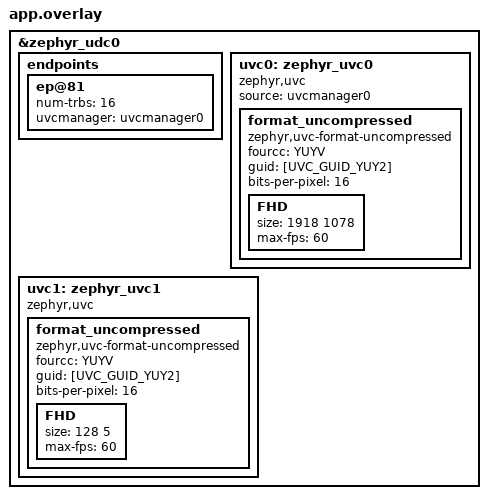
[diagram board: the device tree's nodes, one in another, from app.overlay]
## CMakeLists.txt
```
cmake_minimum_required(VERSION 3.20.0)
find_package(Zephyr REQUIRED HINTS $ENV{ZEPHYR_BASE})
project(app)
target_sources(app PRIVATE src/main.c src/imx219.c src/csrtst.c)

# Run some code from RAM for performance during enumeration
zephyr_code_relocate(LIBRARY drivers__usb__udc LOCATION RAM)
```

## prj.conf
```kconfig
CONFIG_ASSERT=y

# Shell
CONFIG_SHELL=y
CONFIG_I2C_SHELL=y
CONFIG_KERNEL_SHELL=y
CONFIG_SHELL_BACKEND_SERIAL_CHECK_DTR=y

# Logging
CONFIG_LOG=y
CONFIG_LOG_MODE_MINIMAL=y
CONFIG_UDC_DRIVER_LOG_LEVEL_INF=y
CONFIG_USBD_LOG_LEVEL_INF=y
CONFIG_USBD_UVC_LOG_LEVEL_INF=y
CONFIG_VIDEO_LOG_LEVEL_INF=y

# USB
CONFIG_USBD_VIDEO_CLASS=y
CONFIG_USBD_VIDEO_HEADER_SIZE=8

# Video
CONFIG_VIDEO=y
CONFIG_VIDEO_IMX219=y
# CONFIG_VIDEO_IMX219_DUMMY=y
CONFIG_VIDEO_UVCMANAGER=y

# I2C
CONFIG_I2C_PCA9542A_ROOT_INIT_PRIO=1
CONFIG_I2C_PCA9542A_CHANNEL_INIT_PRIO=2
CONFIG_I2C_PCA9542A_IGNORE_FAILURE=y
```

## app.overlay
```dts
#include <zephyr/dt-bindings/usb/video.h>

/*
 * This builds a complete configuration chain through "source = <&...>;":
 * - USB Video Class (UVC), exposing the controls to the host and communicating with it.
 * - UVC Manager, controlled by the UVC class protocol, doing I/O between the sensor and USB.
 * - IMX219 sensor, with configuration coming from the UVC Manager and the host before it.
 */

&zephyr_udc0 {
	endpoints {
		ep@81 {
			num-trbs = <16>;
			uvcmanager = <&uvcmanager0>;
		};
	};

	uvc0: zephyr_uvc0 {
		compatible = "zephyr,uvc";
		source = <&uvcmanager0>;
		status = "okay";

		format_uncompressed {
			compatible = "zephyr,uvc-format-uncompressed", "zephyr,uvc-format";
			fourcc = "YUYV";
			guid = [UVC_GUID_YUY2];
			bits-per-pixel = <16>;

			FHD {
				/* There are 2 rows and columns less as required to do debayer. */
				size = <1918 1078>;
				max-fps = <60>;
			};
		};
	};

	uvc1: zephyr_uvc1 {
		compatible = "zephyr,uvc";
		status = "okay";

		format_uncompressed {
			compatible = "zephyr,uvc-format-uncompressed", "zephyr,uvc-format";
			fourcc = "YUYV";
			guid = [UVC_GUID_YUY2];
			bits-per-pixel = <16>;

			FHD {
				/* There are 2 rows and columns less as required to do debayer. */
				size = <128 5>;
				max-fps = <60>;
			};
		};
	};

};
```

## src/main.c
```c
#include <zephyr/kernel.h>
#include <zephyr/devicetree.h>
#include <zephyr/drivers/video.h>
#include <zephyr/logging/log.h>

LOG_MODULE_REGISTER(app, LOG_LEVEL_DBG);

static const struct device *uvc0_dev = DEVICE_DT_GET(DT_NODELABEL(uvc0));
static const struct device *uvc1_dev = DEVICE_DT_GET(DT_NODELABEL(uvc1));

int main(void)
{
    printf("hello\n");
    k_sleep(K_SECONDS(5));
    printf("test1......\n");

    const struct device *video_dev = DEVICE_DT_GET(DT_NODELABEL(imx219));
    if (video_dev == NULL || !device_is_ready(video_dev))
    {
        printf("Could not get I2C cam device\n");
        return;
    }
	printk("Video device: %s\n", video_dev->name);

}
```

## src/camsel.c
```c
#include <stdio.h>
#include <zephyr/drivers/i2c.h>
#include <zephyr/shell/shell.h>
#define MUX_ADDR 0x71

static void sel_cam() {

    const struct device *mux_dev = DEVICE_DT_GET(DT_NODELABEL(i2c0));
    if (mux_dev == NULL || !device_is_ready(mux_dev))
    {
        printf("Could not get I2C mux device\n");
        return;
    }

	printf("Selecting camera \n\r");
	uint8_t val = 0x4;
	int ret = i2c_reg_write_byte(mux_dev, MUX_ADDR,
                             0, val);
    if (ret)
    {
        printf("Unable write to Cam. (err %i)\n", ret);
        return;
    }
    printf("Cam 0 selected\n");
    k_sleep(K_SECONDS(1));
}



SHELL_STATIC_SUBCMD_SET_CREATE(cam_sel_sub,
                               SHELL_CMD(sel_cam, NULL, "Select camera 10",
                                         &sel_cam),
                               SHELL_SUBCMD_SET_END);

SHELL_CMD_REGISTER(cam_sel, &cam_sel_sub, "camera selector command", NULL);
```

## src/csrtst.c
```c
#include <stdio.h>
#include <zephyr/shell/shell.h>

#define WISHBONE_BASE_ADDR		0xb0000000


static void reg_32b_read(unsigned int addr, unsigned int *val)
{
	*val = *((volatile unsigned int *)addr);
}

static void CsrRegTest(void) {
	unsigned int val, adr;

	// Read back a bunch of registers from the CSR
	adr = WISHBONE_BASE_ADDR + 0x02000000;
	for (int i = 0; i<=10; i++) {
		reg_32b_read(adr, &val);
		printf("0x%x = 0x%x\n\r", adr, val);
		adr += 4;
	}
}


SHELL_CMD_REGISTER(csr_test, NULL, "Dump CSR registers", CsrRegTest);
```

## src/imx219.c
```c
#include <stdio.h>
#include <zephyr/shell/shell.h>
#include <zephyr/drivers/video.h>
const struct device *video_dev = DEVICE_DT_GET(DT_NODELABEL(imx219));

static void cam_init() {

    //const struct device *video_dev = DEVICE_DT_GET(DT_NODELABEL(imx219));
    if (video_dev == NULL)
    {
        printf("Could not get IMX219 device\n");
        return;
    }
    
	printf("Video device: %s\n", video_dev->name);

    int ret = device_init(video_dev);
    if(ret != 0){
        printf("device not found or failed to init\n");
        return;
    }

    printf("Device initialized successfully ......\n");
}

static void cam_start() {
    
    struct video_format fmt;
    struct video_caps caps;
    int i = 0;

    //const struct device *video_dev = DEVICE_DT_GET(DT_NODELABEL(imx219));
    if (video_dev == NULL || !device_is_ready(video_dev))
    {
        printf("Could not get I2C cam device\n");
        return;
    }
	printf("Video device: %s\n", video_dev->name);

    /* Get capabilities */
	if (video_get_caps(video_dev, VIDEO_EP_OUT, &caps)) {
		printf("Unable to retrieve video capabilities\n");
		return;
	}

	printf("Capabilities:\n");
	while (caps.format_caps[i].pixelformat) {
		const struct video_format_cap *fcap = &caps.format_caps[i];
		/* fourcc to string */
		printf("  %c%c%c%c width [%u; %u; %u] height [%u; %u; %u]\n",
		       (char)fcap->pixelformat, (char)(fcap->pixelformat >> 8),
		       (char)(fcap->pixelformat >> 16), (char)(fcap->pixelformat >> 24),
		       fcap->width_min, fcap->width_max, fcap->width_step, fcap->height_min,
		       fcap->height_max, fcap->height_step);
		i++;
	}

    if (video_get_format(video_dev, VIDEO_EP_OUT, &fmt)) {
		printf("Unable to retrieve video format\n");
		return;
	}

	printf("Default format: %c%c%c%c %ux%u\n", (char)fmt.pixelformat,
	       (char)(fmt.pixelformat >> 8), (char)(fmt.pixelformat >> 16),
	       (char)(fmt.pixelformat >> 24), fmt.width, fmt.height);


    /* Start video capture */
	if (video_stream_start(video_dev)) {
		printf("Unable to start capture (interface)\n");
		return;
	}
    printf("Streaming......\n");
}

static void cam_stop() {

    //const struct device *video_dev = DEVICE_DT_GET(DT_NODELABEL(imx219));
    if (video_dev == NULL || !device_is_ready(video_dev))
    {
        printf("Could not get I2C cam device\n");
        return;
    }
	printf("Video device: %s\n", video_dev->name);

	if (video_stream_stop(video_dev)) {
		printf("Unable to start capture (interface)\n");
		return;
	}
    printf("stoping camera......\n");
}

SHELL_STATIC_SUBCMD_SET_CREATE(cam_sub,
                                SHELL_CMD(cam_init, NULL, "Initialize camera",
                                         &cam_init),
                                SHELL_CMD(cam_start, NULL, "start camera streaming",
                                         &cam_start),
                                SHELL_CMD(cam_stop, NULL, "stop camera streaming",
                                         &cam_stop),      
                               SHELL_SUBCMD_SET_END);

SHELL_CMD_REGISTER(imx219, &cam_sub, "camera command", NULL);
```
